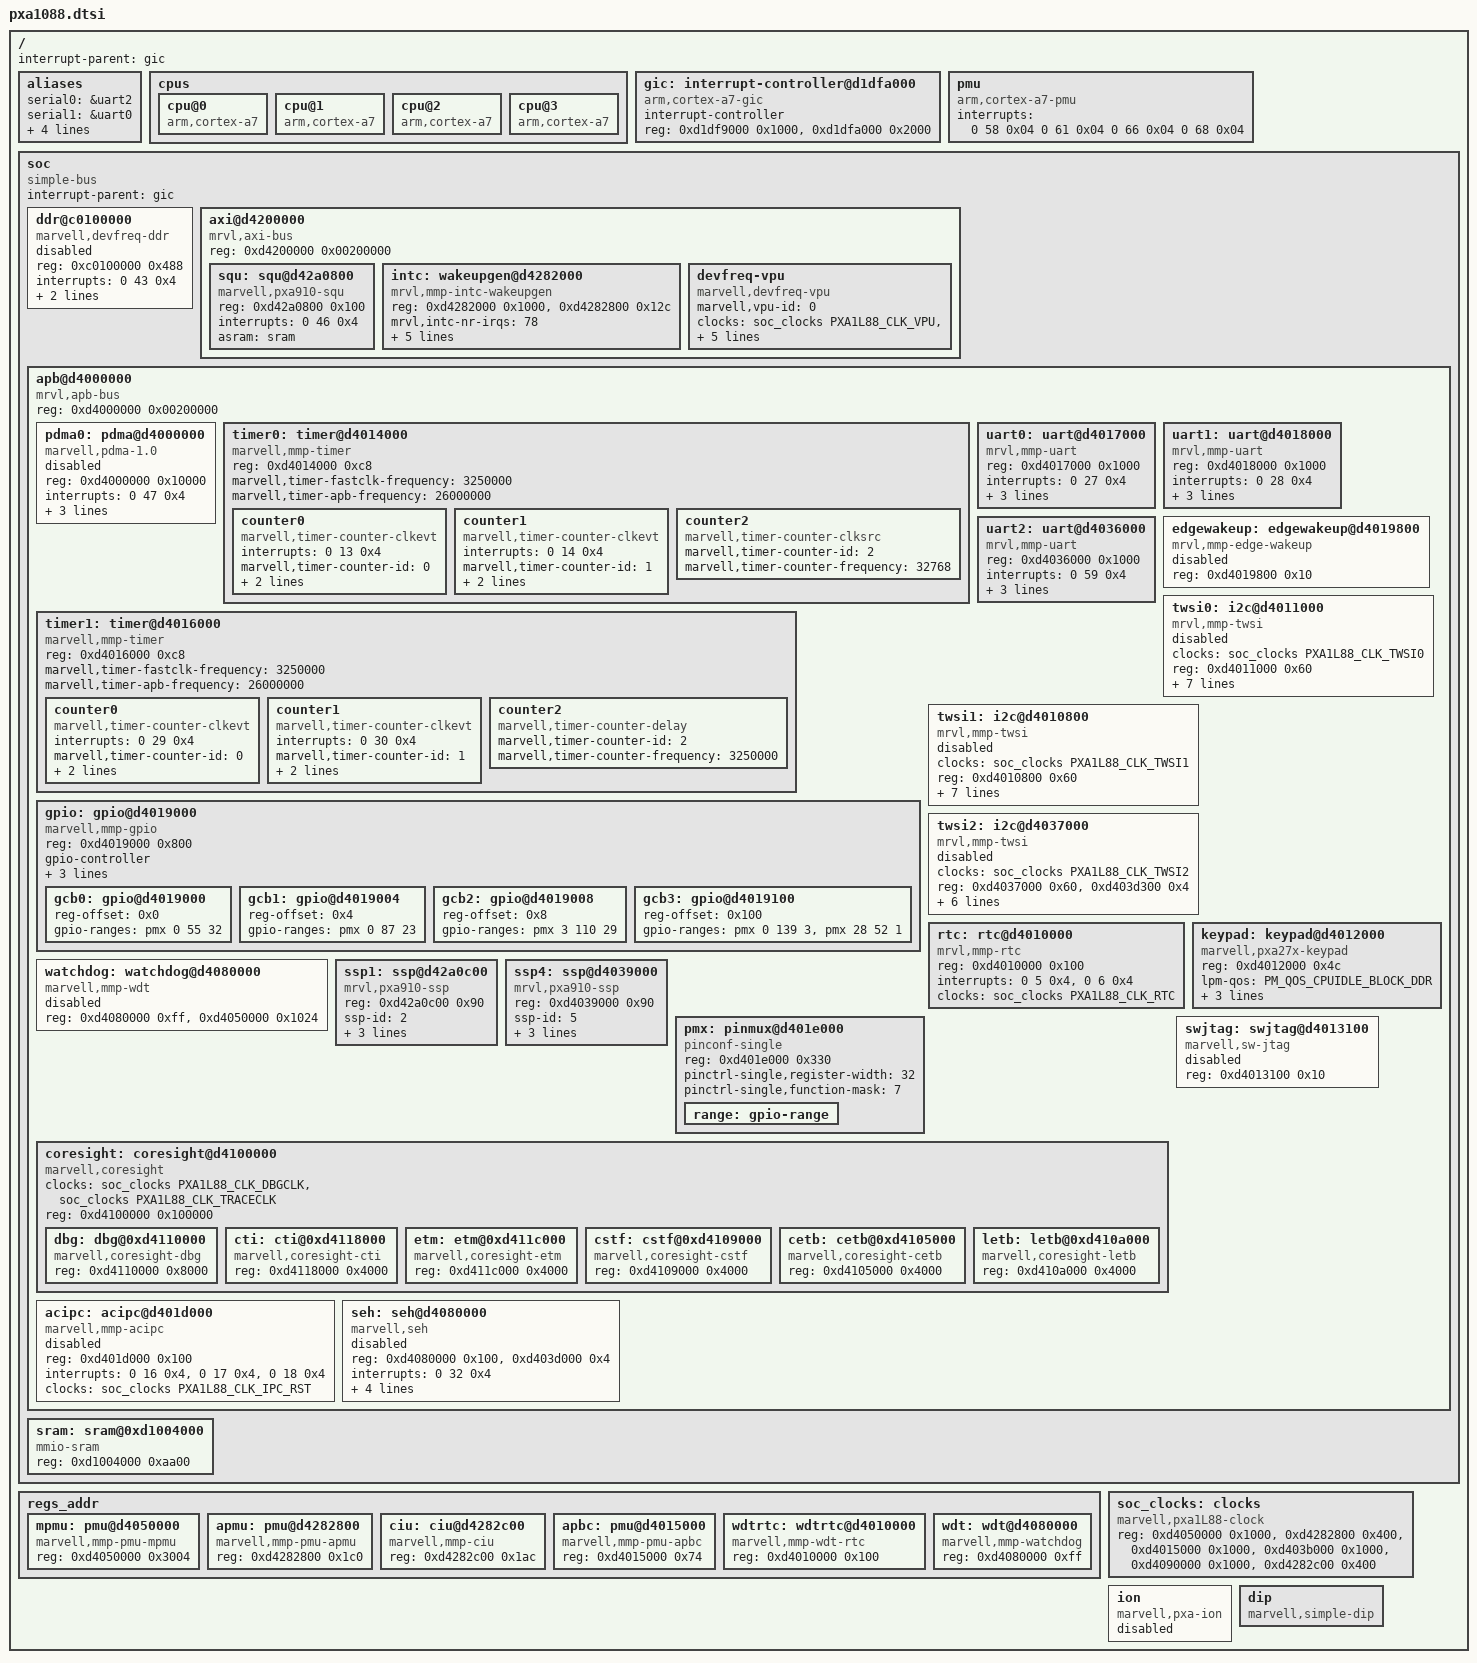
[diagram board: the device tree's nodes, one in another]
/*
 *  Copyright (C) 2013 Marvell Technology Group Ltd.
 *  Author: Chao Xie <chao.xie@marvell.com>
 *
 *  This program is free software; you can redistribute it and/or modify
 *  it under the terms of the GNU General Public License version 2 as
 *  publishhed by the Free Software Foundation.
 */

/include/ "skeleton.dtsi"
#include "pxa988-pinfunc.h"
#include "pxa1U88-pm.h"
#include <dt-bindings/clock/marvell-pxa1L88.h>

/ {
	interrupt-parent = <&gic>;

	aliases {
		serial0 = &uart2;
		serial1 = &uart0;
		serial2 = &uart1;
		i2c0 = &twsi0;
		i2c1 = &twsi1;
		i2c2 = &twsi2;
	};

	cpus {
		cpu@0 {
			compatible = "arm,cortex-a7";
		};
		cpu@1 {
			compatible = "arm,cortex-a7";
		};
		cpu@2 {
			compatible = "arm,cortex-a7";
		};
		cpu@3 {
			compatible = "arm,cortex-a7";
		};
	};

	gic: interrupt-controller@d1dfa000 {
		compatible = "arm,cortex-a7-gic";
		interrupt-controller;
		#interrupt-cells = <3>;
		reg = <0xd1df9000 0x1000>,
		      <0xd1dfa000 0x2000>;
	};

	pmu {
		compatible = "arm,cortex-a7-pmu";
		interrupts = <0 58 0x04
			      0 61 0x04
			      0 66 0x04
			      0 68 0x04>;
	};

	soc {
		#address-cells = <1>;
		#size-cells = <1>;
		compatible = "simple-bus";
		interrupt-parent = <&gic>;
		ranges;

		ddr@c0100000 {  /* DDR memory controller */
			compatible = "marvell,devfreq-ddr";
			reg = <0xc0100000 0x488>;
			interrupts = <0 43 0x4>;
			clocks = <&soc_clocks PXA1L88_CLK_DDR>;
			marvell,qos;
			status = "disabled";
		};

		axi@d4200000 {	/* AXI */
			compatible = "mrvl,axi-bus", "simple-bus";
			#address-cells = <1>;
			#size-cells = <1>;
			reg = <0xd4200000 0x00200000>;
			ranges;

			squ: squ@d42a0800 {
				compatible = "marvell,pxa910-squ";
				reg = <0xd42a0800 0x100>;
				interrupts = <0 46 0x4>;
				#dma-cells = <1>;
				asram = <&sram>;
			};

			intc: wakeupgen@d4282000 {
				compatible = "mrvl,mmp-intc-wakeupgen";
				reg = <0xd4282000 0x1000>,
				      <0xd4282800 0x12c>;
				mrvl,intc-nr-irqs = <78>;
				mrvl,intc-gbl-mask = <0x228 0x3
						      0x238 0x3
						      0x248 0x3
						      0x258 0x3>;
				mrvl,intc-for-cp = <0 31 32>;
				mrvl,intc-wake-clr = <9  (1 << 3)
						      39 (1 << 0 | 1 << 1 | 1 << 6)>;
			};

			devfreq-vpu {
				compatible = "marvell,devfreq-vpu";
				marvell,vpu-id = <0>;
				clocks = <&soc_clocks PXA1L88_CLK_VPU
					  &soc_clocks PXA1L88_CLK_VPUBUS>;
				clock-names = "vpu-fclk", "vpu-bclk";
				marvell,mmp-clk-freq-combine =
						<156000 156000>,
						<208000 208000>,
						<312000 312000>,
						<416000 416000>,
						<533000 533000>;
				marvell,qos;
			};
		};

		apb@d4000000 {	/* APB */
			compatible = "mrvl,apb-bus", "simple-bus";
			#address-cells = <1>;
			#size-cells = <1>;
			reg = <0xd4000000 0x00200000>;
			ranges;

			pdma0: pdma@d4000000 {
				compatible = "marvell,pdma-1.0";
				reg = <0xd4000000 0x10000>;
				interrupts = <0 47 0x4>;
				#dma-cells= <2>;
				#dma-channels = <32>;
				#dma-channels-tz = <30>;
				lpm-qos = <PM_QOS_CPUIDLE_BLOCK_AXI>;
				status = "disabled";
			};

			timer0: timer@d4014000 {
				compatible = "marvell,mmp-timer";
				reg = <0xd4014000 0xc8>;
				marvell,timer-fastclk-frequency = <3250000>;
				marvell,timer-apb-frequency = <26000000>;

				counter0 {
					compatible = "marvell,timer-counter-clkevt";
					interrupts = <0 13 0x4>;
					marvell,timer-counter-id = <0>;
					marvell,timer-counter-cpu = <0>;
					marvell,timer-counter-frequency = <32768>;
				};

				counter1 {
					compatible = "marvell,timer-counter-clkevt";
					interrupts = <0 14 0x4>;
					marvell,timer-counter-id = <1>;
					marvell,timer-counter-cpu = <1>;
					marvell,timer-counter-frequency = <32768>;
				};

				counter2 {
					compatible = "marvell,timer-counter-clksrc";
					marvell,timer-counter-id = <2>;
					marvell,timer-counter-frequency = <32768>;
				};
			};

			timer1: timer@d4016000 {
				compatible = "marvell,mmp-timer";
				reg = <0xd4016000 0xc8>;
				marvell,timer-fastclk-frequency = <3250000>;
				marvell,timer-apb-frequency = <26000000>;

				counter0 {
					compatible = "marvell,timer-counter-clkevt";
					interrupts = <0 29 0x4>;
					marvell,timer-counter-id = <0>;
					marvell,timer-counter-cpu = <2>;
					marvell,timer-counter-frequency = <32768>;
				};

				counter1 {
					compatible = "marvell,timer-counter-clkevt";
					interrupts = <0 30 0x4>;
					marvell,timer-counter-id = <1>;
					marvell,timer-counter-cpu = <3>;
					marvell,timer-counter-frequency = <32768>;
				};

				counter2 {
					compatible = "marvell,timer-counter-delay";
					marvell,timer-counter-id = <2>;
					marvell,timer-counter-frequency = <3250000>;
				};
			};

			uart0: uart@d4017000 {
				compatible = "mrvl,mmp-uart";
				reg = <0xd4017000 0x1000>;
				interrupts = <0 27 0x4>;
				dmas = <&pdma0 21 1
					&pdma0 22 1>;
				dma-names = "rx", "tx";
				lpm-qos = <PM_QOS_CPUIDLE_BLOCK_AXI>;
				clocks = <&soc_clocks PXA1L88_CLK_UART0>;
			};

			uart1: uart@d4018000 {
				compatible = "mrvl,mmp-uart";
				reg = <0xd4018000 0x1000>;
				interrupts = <0 28 0x4>;
				dmas = <&pdma0 23 1
					&pdma0 24 1>;
				dma-names = "rx", "tx";
				lpm-qos = <PM_QOS_CPUIDLE_BLOCK_AXI>;
				clocks = <&soc_clocks PXA1L88_CLK_UART1>;
			};

			uart2: uart@d4036000 {
				compatible = "mrvl,mmp-uart";
				reg = <0xd4036000 0x1000>;
				interrupts = <0 59 0x4>;
				dmas = <&pdma0 4 1
					&pdma0 5 1>;
				dma-names = "rx", "tx";
				lpm-qos = <PM_QOS_CPUIDLE_BLOCK_AXI>;
				clocks = <&soc_clocks PXA1L88_CLK_UART2>;
			};


			gpio: gpio@d4019000 {
				compatible = "marvell,mmp-gpio";
				#address-cells = <1>;
				#size-cells = <1>;
				reg = <0xd4019000 0x800>;
				gpio-controller;
				#gpio-cells = <2>;
				interrupts = <0 49 0x4>;
				clocks = <&soc_clocks PXA1L88_CLK_GPIO>;
				interrupt-names = "gpio_mux";
				interrupt-controller;
				#interrupt-cells = <2>;
				ranges;

				gcb0: gpio@d4019000 {
					reg-offset = <0x0>;
					gpio-ranges = <&pmx 0 55 32>;
				};

				gcb1: gpio@d4019004 {
					reg-offset = <0x4>;
					gpio-ranges = <&pmx 0 87 23>;
				};

				gcb2: gpio@d4019008 {
					reg-offset = <0x8>;
					gpio-ranges = <&pmx 3 110 29>;
				};

				gcb3: gpio@d4019100 {
					reg-offset = <0x100>;
					gpio-ranges = <&pmx 0 139 3  &pmx 28 52 1>;
				};
			};

			edgewakeup: edgewakeup@d4019800 {
				compatible = "mrvl,mmp-edge-wakeup";
				reg = <0xd4019800 0x10>;
				status = "disabled";
			};

			twsi0: i2c@d4011000 {
				compatible = "mrvl,mmp-twsi";
				#address-cells = <1>;
				#size-cells = <0>;
				clocks = <&soc_clocks PXA1L88_CLK_TWSI0>;
				reg = <0xd4011000 0x60>;
				interrupts = <0 7 0x4>;
				lpm-qos = <PM_QOS_CPUIDLE_BLOCK_DDR>;
				mrvl,i2c-fast-mode;
				/*
				 *ilcr: fast mode b17~9=0x23, 390k
				 *      standard mode b8~0=0x9f, 97k
				 *iwcr: b5~0=b01010 recommended value from spec
				 */
				marvell,i2c-ilcr = <0x82c469f>;
				marvell,i2c-iwcr = <0x142a>;
				marvell,i2c-enable-bus-rst;
				marvell,i2c-gpio-bus-rst;

				status = "disabled";
			};

			twsi1: i2c@d4010800 {
				compatible = "mrvl,mmp-twsi";
				#address-cells = <1>;
				#size-cells = <0>;
				clocks = <&soc_clocks PXA1L88_CLK_TWSI1>;
				reg = <0xd4010800 0x60>;
				interrupts = <0 33 0x4>;
				lpm-qos = <PM_QOS_CPUIDLE_BLOCK_DDR>;

				mrvl,i2c-fast-mode;
				marvell,i2c-ilcr = <0x82c469f>;
				marvell,i2c-iwcr = <0x142a>;
				marvell,i2c-enable-bus-rst;
				marvell,i2c-gpio-bus-rst;

				status = "disabled";
			};

			twsi2: i2c@d4037000 {
				compatible = "mrvl,mmp-twsi";
				#address-cells = <1>;
				#size-cells = <0>;
				clocks = <&soc_clocks PXA1L88_CLK_TWSI2>;
				/* RIPC3 */
				reg = <0xd4037000 0x60>,
				      <0xd403d300 0x4>;
				interrupts = <0 54 0x4>;
				lpm-qos = <PM_QOS_CPUIDLE_BLOCK_DDR>;

				mrvl,i2c-fast-mode;
				marvell,i2c-ilcr = <0x82c469f>;
				marvell,i2c-iwcr = <0x142a>;

				marvell,i2c-always-on;
				status = "disabled";
			};

			rtc: rtc@d4010000 {
				compatible = "mrvl,mmp-rtc";
				reg = <0xd4010000 0x100>;
				interrupts = <0 5 0x4>,<0 6 0x4>;
				interrupt-names = "rtc 1Hz", "rtc alarm";
				clocks = <&soc_clocks PXA1L88_CLK_RTC>;
			};

			watchdog: watchdog@d4080000 {
				compatible = "marvell,mmp-wdt";
				reg = <0xd4080000 0xff>,
				      <0xd4050000 0x1024>;
				status = "disabled";
			};

			keypad: keypad@d4012000 {
				compatible = "marvell,pxa27x-keypad";
				reg = <0xd4012000 0x4c>;
				lpm-qos = <PM_QOS_CPUIDLE_BLOCK_DDR>;
				interrupts = <0 9 0x4>;
				marvell,keypad-lpm-mod;
				clocks = <&soc_clocks PXA1L88_CLK_KPC>;
			};

			ssp1: ssp@d42a0c00 {
				compatible = "mrvl,pxa910-ssp";
				reg = <0xd42a0c00 0x90>;
				ssp-id = <2>;
				interrupts = <0 2 0x4>;
				clocks = <&soc_clocks PXA1L88_CLK_SSP>;
				dmas = <&squ 1
					&squ 0>;
				dma-names = "rx", "tx";
			};

			ssp4: ssp@d4039000 {
				compatible = "mrvl,pxa910-ssp";
				reg = <0xd4039000 0x90>;
				ssp-id = <5>;
				interrupts = <0 34 0x4>;
				clocks = <&soc_clocks PXA1L88_CLK_GSSP>;
				dmas = <&pdma0 6 0
					&pdma0 7 0>;
				dma-names = "rx", "tx";
			};

			pmx: pinmux@d401e000 {
				compatible = "pinconf-single";
				reg = <0xd401e000 0x330>;
				#address-cells = <1>;
				#size-cells = <1>;
				#gpio-range-cells = <3>;
				ranges;

				pinctrl-single,register-width = <32>;
				pinctrl-single,function-mask = <7>;

				range: gpio-range {
					#pinctrl-single,gpio-range-cells = <3>;
				};
			};
			coresight: coresight@d4100000 {
				compatible = "marvell,coresight";
				clocks = <&soc_clocks PXA1L88_CLK_DBGCLK>,
					 <&soc_clocks PXA1L88_CLK_TRACECLK>;
				clock-names = "DBGCLK","TRACECLK";
				#address-cells = <1>;
				#size-cells = <1>;
				reg = <0xd4100000 0x100000>;
				ranges;

				dbg: dbg@0xd4110000 {
					compatible = "marvell,coresight-dbg";
					reg = <0xd4110000 0x8000>;
				};

				cti: cti@0xd4118000 {
					compatible = "marvell,coresight-cti";
				        reg = <0xd4118000 0x4000>;
				};

				etm: etm@0xd411c000 {
					compatible = "marvell,coresight-etm";
				        reg = <0xd411c000 0x4000>;
				};

				cstf: cstf@0xd4109000 {
					compatible = "marvell,coresight-cstf";
				        reg = <0xd4109000 0x4000>;
				};

				cetb: cetb@0xd4105000 {
					compatible = "marvell,coresight-cetb";
				        reg = <0xd4105000 0x4000>;
				};

				letb: letb@0xd410a000 {
					compatible = "marvell,coresight-letb";
				        reg = <0xd410a000 0x4000>;
				};
			};

			swjtag: swjtag@d4013100 {
				compatible = "marvell,sw-jtag";
				reg = <0xd4013100 0x10>;
				status = "disabled";
			};

			acipc: acipc@d401d000 {
				compatible = "marvell,mmp-acipc";
				reg = <0xd401d000 0x100>;
				interrupts = <0 16 0x4>,<0 17 0x4>,<0 18 0x4>;
				interrupt-names = "IPC_AP_DATAACK", "IPC_AP_SET_CMD", "IPC_AP_SET_MSG";
				clocks = <&soc_clocks PXA1L88_CLK_IPC_RST>;
				status = "disabled";
			};

			seh: seh@d4080000 {
				compatible = "marvell,seh";
				reg = <0xd4080000 0x100>, <0xd403d000 0x4>;
				interrupts = <0 32 0x4>;
				interrupt-names = "CP_TIMER2_3";
				clocks = <&soc_clocks PXA1L88_CLK_AICER>;
				watchdog-type = <1>; /* soc timer */
				timer-num = <2>; /* timer num */
				match-num = <0>; /* match num */
				status = "disabled";
			};

		};

		sram: sram@0xd1004000 {
			compatible = "mmio-sram";
			reg = <0xd1004000 0xaa00>;
		};
	};

	regs_addr {
		#address-cells = <1>;
		#size-cells = <1>;
		ranges;

		mpmu: pmu@d4050000 {
			compatible = "marvell,mmp-pmu-mpmu";
			reg = <0xd4050000 0x3004>;
		};

		apmu: pmu@d4282800 {
			compatible = "marvell,mmp-pmu-apmu";
			reg = <0xd4282800 0x1c0>;
		};

		ciu: ciu@d4282c00 {
			compatible = "marvell,mmp-ciu";
			reg = <0xd4282c00 0x1ac>;
		};

		apbc: pmu@d4015000 {
			compatible = "marvell,mmp-pmu-apbc";
			reg = <0xd4015000 0x74>;
		};

		wdtrtc: wdtrtc@d4010000 {
			compatible = "marvell,mmp-wdt-rtc";
			reg = <0xd4010000 0x100>;
		};

		wdt: wdt@d4080000 {
			compatible = "marvell,mmp-watchdog";
			reg = <0xd4080000 0xff>;
		};

	};
	soc_clocks: clocks{
		compatible = "marvell,pxa1L88-clock";
		reg = <0xd4050000 0x1000>,
		      <0xd4282800 0x400>,
		      <0xd4015000 0x1000>,
		      <0xd403b000 0x1000>,
		      <0xd4090000 0x1000>,
		      <0xd4282c00 0x400>;
		reg-names = "mpmu", "apmu", "apbc", "apbcp", "apbs", "ciu";
		#clock-cells = <1>;
        };

	ion {
		compatible = "marvell,pxa-ion";
		status = "disabled";
	};

	dip {
		compatible = "marvell,simple-dip";
	};
};
